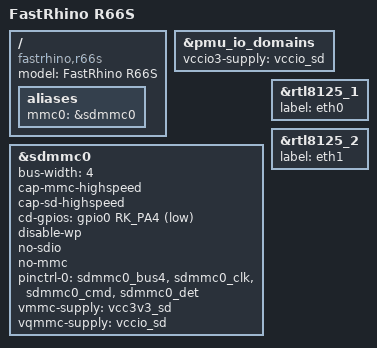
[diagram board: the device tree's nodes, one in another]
// SPDX-License-Identifier: GPL-2.0-or-later OR MIT

#include "rk3568-fastrhino-r66s.dtsi"

/ {
	model = "FastRhino R66S";
	compatible = "fastrhino,r66s", "rockchip,rk3568";

	aliases {
		mmc0 = &sdmmc0;
	};
};

&pmu_io_domains {
	vccio3-supply = <&vccio_sd>;
};

&sdmmc0 {
	bus-width = <4>;
	cap-mmc-highspeed;
	cap-sd-highspeed;
	cd-gpios = <&gpio0 RK_PA4 GPIO_ACTIVE_LOW>;
	disable-wp;
	no-sdio;
	no-mmc;
	pinctrl-names = "default";
	pinctrl-0 = <&sdmmc0_bus4 &sdmmc0_clk &sdmmc0_cmd &sdmmc0_det>;
	vmmc-supply = <&vcc3v3_sd>;
	vqmmc-supply = <&vccio_sd>;
	status = "okay";
};

&rtl8125_1 {
	label = "eth0";
};

&rtl8125_2 {
	label = "eth1";
};
